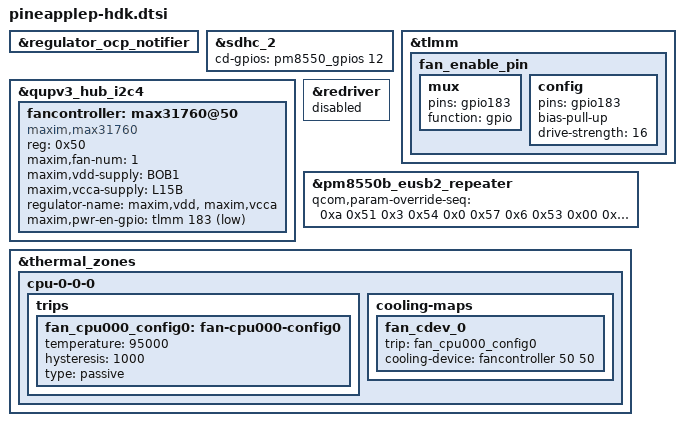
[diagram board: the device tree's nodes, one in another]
#include "pineapple-qrd.dtsi"

&regulator_ocp_notifier {
	/delete-property/ periph-ac1-supply;
	/delete-property/ periph-ac2-supply;
	/delete-property/ periph-ac3-supply;
	/delete-property/ periph-ac4-supply;
	/delete-property/ periph-ac5-supply;
	/delete-property/ periph-ac6-supply;
	/delete-property/ periph-ac7-supply;
};

&sdhc_2 {
	cd-gpios = <&pm8550_gpios 12 GPIO_ACTIVE_HIGH>;
};

&tlmm {
	fan_enable_pin {
		mux {
			pins = "gpio183";
			function = "gpio";
		};

		config {
			pins = "gpio183";
			bias-pull-up;
			drive-strength = <16>;
		};
	};
};

&qupv3_hub_i2c4 {
	status = "ok";
	#address-cells = <1>;
	#size-cells = <0>;

	fancontroller: max31760@50 {
		compatible = "maxim,max31760";
		reg = <0x50>;
		#cooling-cells = <2>;
		maxim,fan-num = <1>;
		maxim,vdd-supply = <&BOB1>;
		maxim,vcca-supply = <&L15B>;
		regulator-name = "maxim,vdd", "maxim,vcca";
		maxim,pwr-en-gpio = <&tlmm 183 GPIO_ACTIVE_LOW>;
		status = "ok";
	};
};

&redriver {
	status = "disabled";
};

&pm8550b_eusb2_repeater {
	qcom,param-override-seq =
		<0xa 0x51
		 0x3 0x54
		 0x0 0x57
		 0x6 0x53
		 0x00 0x59>;
};

&thermal_zones {
	cpu-0-0-0 {
		trips {
			fan_cpu000_config0: fan-cpu000-config0 {
				temperature = <95000>;
				hysteresis = <1000>;
				type = "passive";
			};
		};

		cooling-maps {
			fan_cdev_0 {
				trip = <&fan_cpu000_config0>;
				cooling-device = <&fancontroller 50 50>;
			};
		};
	};
};
